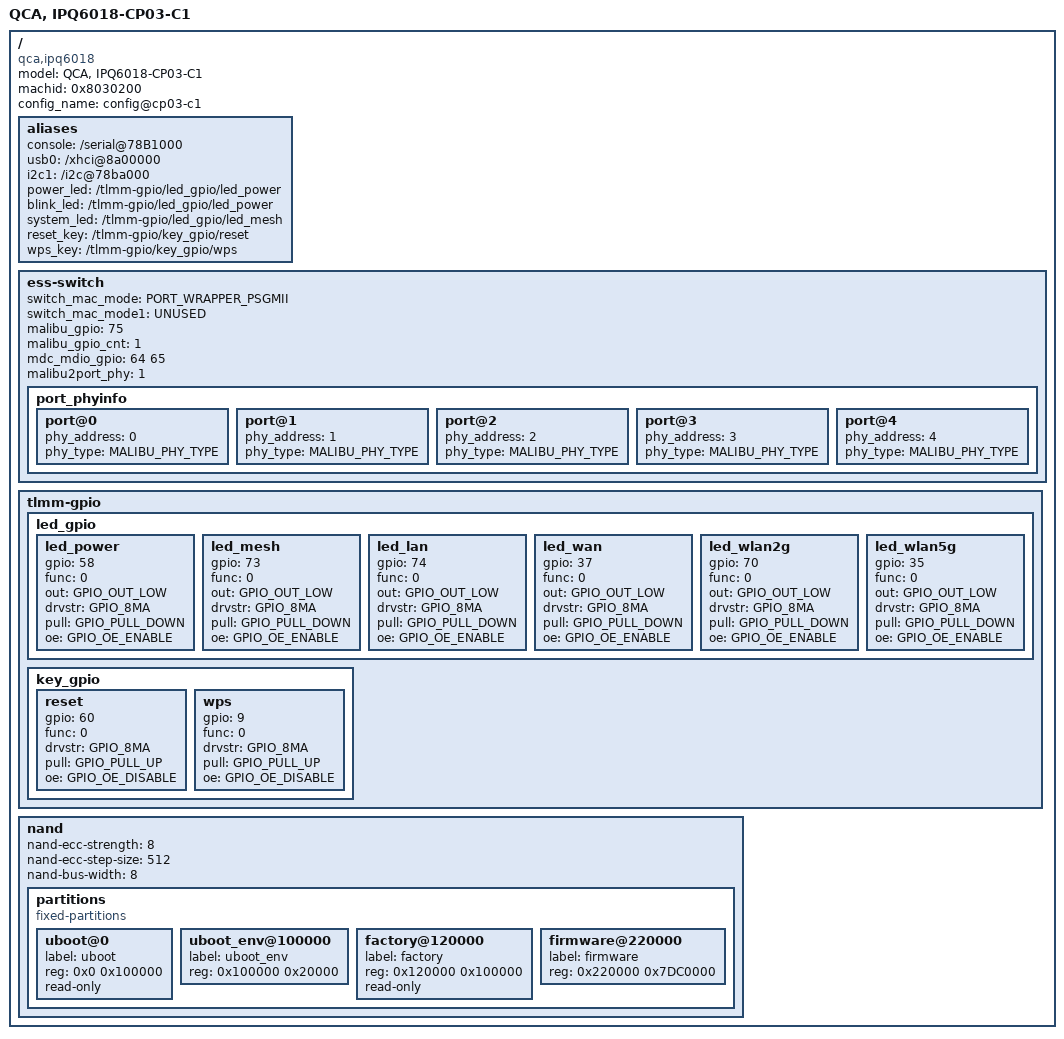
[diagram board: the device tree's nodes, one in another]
/*
 * Copyright (c) 2019, The Linux Foundation. All rights reserved.
 *
 * This program is free software; you can redistribute it and/or modify
 * it under the terms of the GNU General Public License version 2 and
 * only version 2 as published by the Free Software Foundation.
 *
 * This program is distributed in the hope that it will be useful,
 * but WITHOUT ANY WARRANTY; without even the implied warranty of
 * MERCHANTABILITY or FITNESS FOR A PARTICULAR PURPOSE.  See the
 * GNU General Public License for more details.
 */

/dts-v1/;
#include "ipq6018-soc.dtsi"
/ {
	model ="QCA, IPQ6018-CP03-C1";
	compatible = "qca,ipq6018", "qca,ipq6018-cp03-c1";
	machid = <0x8030200>;
	config_name = "config@cp03-c1";

	aliases {
		console = "/serial@78B1000";
		usb0 = "/xhci@8a00000";
		i2c1 = "/i2c@78ba000";
		power_led = "/tlmm-gpio/led_gpio/led_power";
		blink_led = "/tlmm-gpio/led_gpio/led_power";
		system_led = "/tlmm-gpio/led_gpio/led_mesh";
		reset_key = "/tlmm-gpio/key_gpio/reset";
		wps_key = "/tlmm-gpio/key_gpio/wps";
	};

	ess-switch {
		switch_mac_mode = <PORT_WRAPPER_PSGMII>;
		switch_mac_mode1 = <UNUSED>;
		malibu_gpio = <75>;
		malibu_gpio_cnt = <1>;
		mdc_mdio_gpio = <64 65>;
		malibu2port_phy = <1>;
		port_phyinfo {
			port@0 {
				phy_address = <0>;
				phy_type = <MALIBU_PHY_TYPE>;
			};
			port@1 {
				phy_address = <1>;
				phy_type = <MALIBU_PHY_TYPE>;
			};
			port@2 {
				phy_address = <2>;
				phy_type = <MALIBU_PHY_TYPE>;
			};
			port@3 {
				phy_address = <3>;
				phy_type = <MALIBU_PHY_TYPE>;
			};
			port@4 {
				phy_address = <4>;
				phy_type = <MALIBU_PHY_TYPE>;
			};
		};
	};

	tlmm-gpio {
		led_gpio {
			led_power {
				gpio = <58>;
				func = <0>;
				out = <GPIO_OUT_LOW>;
				drvstr = <GPIO_8MA>;
				pull = <GPIO_PULL_DOWN>;
				oe = <GPIO_OE_ENABLE>;
			};
			led_mesh {
				gpio = <73>;
				func = <0>;
				out = <GPIO_OUT_LOW>;
				drvstr = <GPIO_8MA>;
				pull = <GPIO_PULL_DOWN>;
				oe = <GPIO_OE_ENABLE>;
			};
			led_lan {
				gpio = <74>;
				func = <0>;
				out = <GPIO_OUT_LOW>;
				drvstr = <GPIO_8MA>;
				pull = <GPIO_PULL_DOWN>;
				oe = <GPIO_OE_ENABLE>;
			};
			led_wan {
				gpio = <37>;
				func = <0>;
				out = <GPIO_OUT_LOW>;
				drvstr = <GPIO_8MA>;
				pull = <GPIO_PULL_DOWN>;
				oe = <GPIO_OE_ENABLE>;
			};
			led_wlan2g {
				gpio = <70>;
				func = <0>;
				out = <GPIO_OUT_LOW>;
				drvstr = <GPIO_8MA>;
				pull = <GPIO_PULL_DOWN>;
				oe = <GPIO_OE_ENABLE>;
			};
			led_wlan5g {
				gpio = <35>;
				func = <0>;
				out = <GPIO_OUT_LOW>;
				drvstr = <GPIO_8MA>;
				pull = <GPIO_PULL_DOWN>;
				oe = <GPIO_OE_ENABLE>;
			};
		};

		key_gpio {
			reset {
				gpio = <60>;
				func = <0>;
				drvstr = <GPIO_8MA>;
				pull = <GPIO_PULL_UP>;
				oe = <GPIO_OE_DISABLE>;
			};
			wps {
				gpio = <9>;
				func = <0>;
				drvstr = <GPIO_8MA>;
				pull = <GPIO_PULL_UP>;
				oe = <GPIO_OE_DISABLE>;
			};
		};
	};

	nand {
		status = "okay";          // 启用NAND闪存
		nand-ecc-strength = <8>;  // 适配S34MS04G100TFI000的8bit ECC
		nand-ecc-step-size = <512>;
		nand-bus-width = <8>;     // 8位总线，匹配闪存规格

		partitions {
			compatible = "fixed-partitions";
			#address-cells = <1>;
			#size-cells = <1>;

			// 分区1：uboot（1MB=0x100000），起始地址0x0
			uboot@0 {
				label = "uboot";
				reg = <0x0 0x100000>;
				read-only;  // 只读，防止误擦除
			};

			// 分区2：uboot_env（128KB=0x20000），起始地址0x100000
			uboot_env@100000 {
				label = "uboot_env";
				reg = <0x100000 0x20000>;
			};

			// 分区3：factory（1MB=0x100000），起始地址0x120000
			factory@120000 {
				label = "factory";
				reg = <0x120000 0x100000>;
				read-only;  // 只读，保护MAC/校准数据
			};

			// 分区4：firmware（510976KB=0x7DC0000），起始地址0x220000
			// 计算：512MB=0x20000000 - 0x100000(uboot) - 0x20000(uboot_env) - 0x100000(factory) = 0x7DC0000
			firmware@220000 {
				label = "firmware";
				reg = <0x220000 0x7DC0000>;
			};
		};
	};
};
